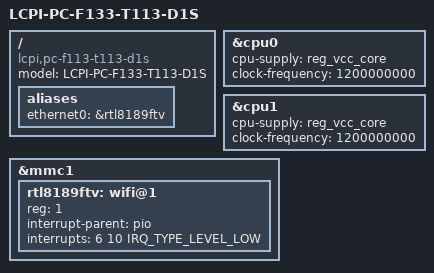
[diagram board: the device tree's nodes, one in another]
// SPDX-License-Identifier: (GPL-2.0+ OR MIT)
// Copyright (C) 2022 Arm Ltd.

#include <dt-bindings/interrupt-controller/irq.h>

/dts-v1/;

#include "sun8i-t113s.dtsi"
#include "sunxi-d1s-t113-lcpi.dtsi"

/ {
	model = "LCPI-PC-F133-T113-D1S";
	compatible = "lcpi,pc-f113-t113-d1s", "allwinner,sun8i-t113s";

	aliases {
		ethernet0 = &rtl8189ftv;
	};
};

&cpu0 {
	cpu-supply = <&reg_vcc_core>;
	clock-frequency = <1200000000>;
};

&cpu1 {
	cpu-supply = <&reg_vcc_core>;
	clock-frequency = <1200000000>;
};

&mmc1 {
	rtl8189ftv: wifi@1 {
		reg = <1>;
		interrupt-parent = <&pio>;
		interrupts = <6 10 IRQ_TYPE_LEVEL_LOW>; /* PG10 = WL_WAKE_AP */
		interrupt-names = "host-wake";
	};
};
